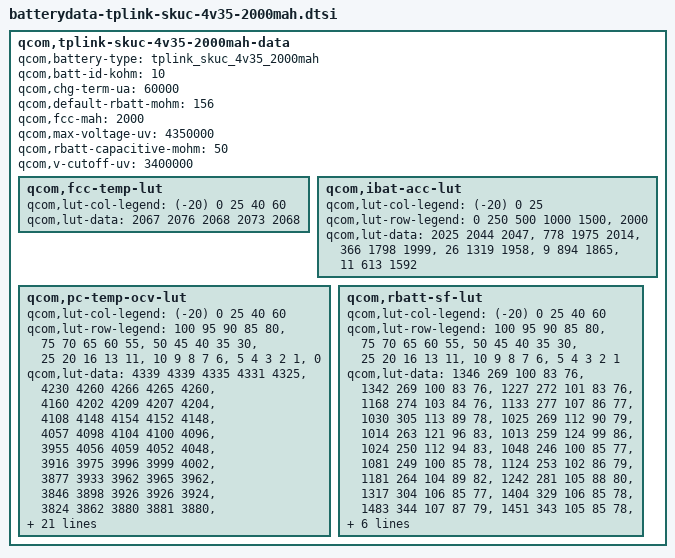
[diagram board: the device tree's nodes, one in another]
/* Copyright (c) 2014, The Linux Foundation. All rights reserved.
 *
 * This program is free software; you can redistribute it and/or modify
 * it under the terms of the GNU General Public License version 2 and
 * only version 2 as published by the Free Software Foundation.
 *
 * This program is distributed in the hope that it will be useful,
 * but WITHOUT ANY WARRANTY; without even the implied warranty of
 * MERCHANTABILITY or FITNESS FOR A PARTICULAR PURPOSE.  See the
 * GNU General Public License for more details.
 */

qcom,tplink-skuc-4v35-2000mah-data {
	qcom,battery-type = "tplink_skuc_4v35_2000mah";
	qcom,batt-id-kohm = <10>;
	qcom,chg-term-ua = <60000>;
	qcom,default-rbatt-mohm = <156>;
	qcom,fcc-mah = <2000>;
	qcom,max-voltage-uv = <4350000>;
	qcom,rbatt-capacitive-mohm = <50>;
	qcom,v-cutoff-uv = <3400000>;

	qcom,fcc-temp-lut {
		qcom,lut-col-legend = <(-20) 0 25 40 60>;
		qcom,lut-data = <2067 2076 2068 2073 2068>;
	};

	qcom,ibat-acc-lut {
		qcom,lut-col-legend = <(-20) 0 25>;
		qcom,lut-row-legend = <0 250 500 1000 1500>,
					<2000>;
		qcom,lut-data = <2025 2044 2047>,
				<778 1975 2014>,
				<366 1798 1999>,
				<26 1319 1958>,
				<9 894 1865>,
				<11 613 1592>;
	};

	qcom,pc-temp-ocv-lut {
		qcom,lut-col-legend = <(-20) 0 25 40 60>;
		qcom,lut-row-legend = <100 95 90 85 80>,
					<75 70 65 60 55>,
					<50 45 40 35 30>,
					<25 20 16 13 11>,
					<10 9 8 7 6>,
					<5 4 3 2 1>,
					<0>;
		qcom,lut-data = <4339 4339 4335 4331 4325>,
				<4230 4260 4266 4265 4260>,
				<4160 4202 4209 4207 4204>,
				<4108 4148 4154 4152 4148>,
				<4057 4098 4104 4100 4096>,
				<3955 4056 4059 4052 4048>,
				<3916 3975 3996 3999 4002>,
				<3877 3933 3962 3965 3962>,
				<3846 3898 3926 3926 3924>,
				<3824 3862 3880 3881 3880>,
				<3808 3832 3841 3842 3842>,
				<3793 3810 3818 3818 3818>,
				<3780 3792 3798 3800 3798>,
				<3766 3781 3784 3784 3783>,
				<3753 3772 3772 3769 3763>,
				<3738 3758 3760 3751 3739>,
				<3722 3740 3742 3732 3718>,
				<3706 3718 3719 3710 3696>,
				<3691 3704 3695 3686 3674>,
				<3678 3697 3689 3681 3669>,
				<3669 3695 3688 3680 3668>,
				<3659 3692 3686 3679 3667>,
				<3647 3688 3685 3678 3666>,
				<3632 3684 3682 3675 3663>,
				<3612 3676 3677 3668 3654>,
				<3586 3654 3658 3646 3629>,
				<3553 3612 3618 3604 3586>,
				<3504 3554 3556 3546 3528>,
				<3430 3470 3476 3466 3443>,
				<3304 3338 3348 3340 3310>,
				<3000 3054 3000 3000 3000>;
	};

	qcom,rbatt-sf-lut {
		qcom,lut-col-legend = <(-20) 0 25 40 60>;
		qcom,lut-row-legend = <100 95 90 85 80>,
					<75 70 65 60 55>,
					<50 45 40 35 30>,
					<25 20 16 13 11>,
					<10 9 8 7 6>,
					<5 4 3 2 1>;
		qcom,lut-data = <1346 269 100 83 76>,
				<1342 269 100 83 76>,
				<1227 272 101 83 76>,
				<1168 274 103 84 76>,
				<1133 277 107 86 77>,
				<1030 305 113 89 78>,
				<1025 269 112 90 79>,
				<1014 263 121 96 83>,
				<1013 259 124 99 86>,
				<1024 250 112 94 83>,
				<1048 246 100 85 77>,
				<1081 249 100 85 78>,
				<1124 253 102 86 79>,
				<1181 264 104 89 82>,
				<1242 281 105 88 80>,
				<1317 304 106 85 77>,
				<1404 329 106 85 78>,
				<1483 344 107 87 79>,
				<1451 343 105 85 78>,
				<1510 364 105 85 78>,
				<1554 383 106 87 79>,
				<1595 401 108 89 81>,
				<1640 424 112 91 82>,
				<1735 452 114 92 85>,
				<1919 481 118 94 86>,
				<2164 500 118 92 82>,
				<2512 530 116 92 83>,
				<3047 588 122 95 85>,
				<4015 678 132 101 92>,
				<8029 1304 210 121 115>;
	};
};
/* TEST_DB_ID=TEST_ID_NOT_SET */
